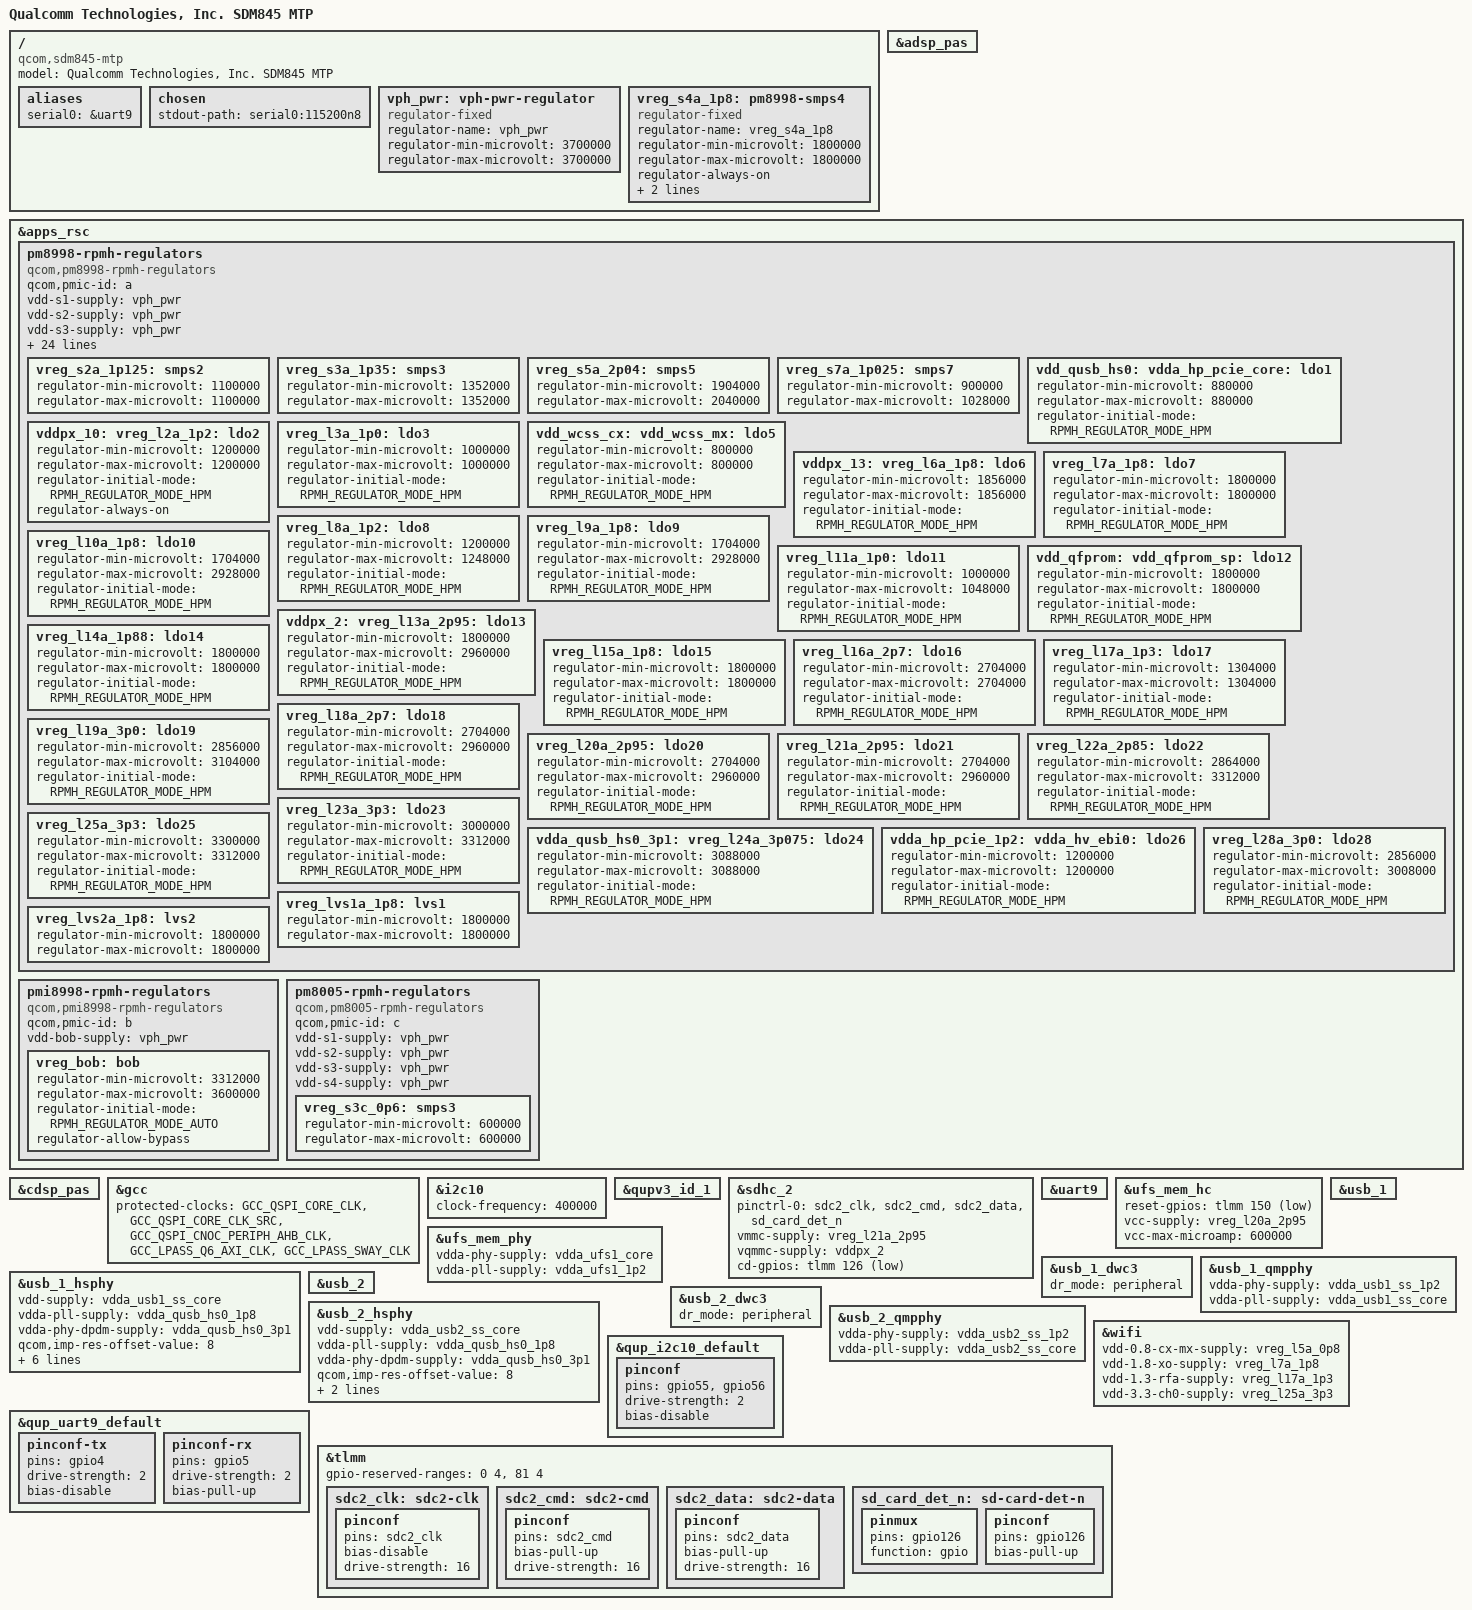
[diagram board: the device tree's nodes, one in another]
// SPDX-License-Identifier: GPL-2.0
/*
 * SDM845 MTP board device tree source
 *
 * Copyright (c) 2018, The Linux Foundation. All rights reserved.
 */

/dts-v1/;

#include <dt-bindings/gpio/gpio.h>
#include <dt-bindings/regulator/qcom,rpmh-regulator.h>
#include "sdm845.dtsi"

/ {
	model = "Qualcomm Technologies, Inc. SDM845 MTP";
	compatible = "qcom,sdm845-mtp";

	aliases {
		serial0 = &uart9;
	};

	chosen {
		stdout-path = "serial0:115200n8";
	};

	vph_pwr: vph-pwr-regulator {
		compatible = "regulator-fixed";
		regulator-name = "vph_pwr";
		regulator-min-microvolt = <3700000>;
		regulator-max-microvolt = <3700000>;
	};

	/*
	 * Apparently RPMh does not provide support for PM8998 S4 because it
	 * is always-on; model it as a fixed regulator.
	 */
	vreg_s4a_1p8: pm8998-smps4 {
		compatible = "regulator-fixed";
		regulator-name = "vreg_s4a_1p8";

		regulator-min-microvolt = <1800000>;
		regulator-max-microvolt = <1800000>;

		regulator-always-on;
		regulator-boot-on;

		vin-supply = <&vph_pwr>;
	};
};

&adsp_pas {
	status = "okay";
};

&apps_rsc {
	pm8998-rpmh-regulators {
		compatible = "qcom,pm8998-rpmh-regulators";
		qcom,pmic-id = "a";

		vdd-s1-supply = <&vph_pwr>;
		vdd-s2-supply = <&vph_pwr>;
		vdd-s3-supply = <&vph_pwr>;
		vdd-s4-supply = <&vph_pwr>;
		vdd-s5-supply = <&vph_pwr>;
		vdd-s6-supply = <&vph_pwr>;
		vdd-s7-supply = <&vph_pwr>;
		vdd-s8-supply = <&vph_pwr>;
		vdd-s9-supply = <&vph_pwr>;
		vdd-s10-supply = <&vph_pwr>;
		vdd-s11-supply = <&vph_pwr>;
		vdd-s12-supply = <&vph_pwr>;
		vdd-s13-supply = <&vph_pwr>;
		vdd-l1-l27-supply = <&vreg_s7a_1p025>;
		vdd-l2-l8-l17-supply = <&vreg_s3a_1p35>;
		vdd-l3-l11-supply = <&vreg_s7a_1p025>;
		vdd-l4-l5-supply = <&vreg_s7a_1p025>;
		vdd-l6-supply = <&vph_pwr>;
		vdd-l7-l12-l14-l15-supply = <&vreg_s5a_2p04>;
		vdd-l9-supply = <&vreg_bob>;
		vdd-l10-l23-l25-supply = <&vreg_bob>;
		vdd-l13-l19-l21-supply = <&vreg_bob>;
		vdd-l16-l28-supply = <&vreg_bob>;
		vdd-l18-l22-supply = <&vreg_bob>;
		vdd-l20-l24-supply = <&vreg_bob>;
		vdd-l26-supply = <&vreg_s3a_1p35>;
		vin-lvs-1-2-supply = <&vreg_s4a_1p8>;

		vreg_s2a_1p125: smps2 {
			regulator-min-microvolt = <1100000>;
			regulator-max-microvolt = <1100000>;
		};

		vreg_s3a_1p35: smps3 {
			regulator-min-microvolt = <1352000>;
			regulator-max-microvolt = <1352000>;
		};

		vreg_s5a_2p04: smps5 {
			regulator-min-microvolt = <1904000>;
			regulator-max-microvolt = <2040000>;
		};

		vreg_s7a_1p025: smps7 {
			regulator-min-microvolt = <900000>;
			regulator-max-microvolt = <1028000>;
		};

		vdd_qusb_hs0:
		vdda_hp_pcie_core:
		vdda_mipi_csi0_0p9:
		vdda_mipi_csi1_0p9:
		vdda_mipi_csi2_0p9:
		vdda_mipi_dsi0_pll:
		vdda_mipi_dsi1_pll:
		vdda_qlink_lv:
		vdda_qlink_lv_ck:
		vdda_qrefs_0p875:
		vdda_pcie_core:
		vdda_pll_cc_ebi01:
		vdda_pll_cc_ebi23:
		vdda_sp_sensor:
		vdda_ufs1_core:
		vdda_ufs2_core:
		vdda_usb1_ss_core:
		vdda_usb2_ss_core:
		vreg_l1a_0p875: ldo1 {
			regulator-min-microvolt = <880000>;
			regulator-max-microvolt = <880000>;
			regulator-initial-mode = <RPMH_REGULATOR_MODE_HPM>;
		};

		vddpx_10:
		vreg_l2a_1p2: ldo2 {
			regulator-min-microvolt = <1200000>;
			regulator-max-microvolt = <1200000>;
			regulator-initial-mode = <RPMH_REGULATOR_MODE_HPM>;
			regulator-always-on;
		};

		vreg_l3a_1p0: ldo3 {
			regulator-min-microvolt = <1000000>;
			regulator-max-microvolt = <1000000>;
			regulator-initial-mode = <RPMH_REGULATOR_MODE_HPM>;
		};

		vdd_wcss_cx:
		vdd_wcss_mx:
		vdda_wcss_pll:
		vreg_l5a_0p8: ldo5 {
			regulator-min-microvolt = <800000>;
			regulator-max-microvolt = <800000>;
			regulator-initial-mode = <RPMH_REGULATOR_MODE_HPM>;
		};

		vddpx_13:
		vreg_l6a_1p8: ldo6 {
			regulator-min-microvolt = <1856000>;
			regulator-max-microvolt = <1856000>;
			regulator-initial-mode = <RPMH_REGULATOR_MODE_HPM>;
		};

		vreg_l7a_1p8: ldo7 {
			regulator-min-microvolt = <1800000>;
			regulator-max-microvolt = <1800000>;
			regulator-initial-mode = <RPMH_REGULATOR_MODE_HPM>;
		};

		vreg_l8a_1p2: ldo8 {
			regulator-min-microvolt = <1200000>;
			regulator-max-microvolt = <1248000>;
			regulator-initial-mode = <RPMH_REGULATOR_MODE_HPM>;
		};

		vreg_l9a_1p8: ldo9 {
			regulator-min-microvolt = <1704000>;
			regulator-max-microvolt = <2928000>;
			regulator-initial-mode = <RPMH_REGULATOR_MODE_HPM>;
		};

		vreg_l10a_1p8: ldo10 {
			regulator-min-microvolt = <1704000>;
			regulator-max-microvolt = <2928000>;
			regulator-initial-mode = <RPMH_REGULATOR_MODE_HPM>;
		};

		vreg_l11a_1p0: ldo11 {
			regulator-min-microvolt = <1000000>;
			regulator-max-microvolt = <1048000>;
			regulator-initial-mode = <RPMH_REGULATOR_MODE_HPM>;
		};

		vdd_qfprom:
		vdd_qfprom_sp:
		vdda_apc1_cs_1p8:
		vdda_gfx_cs_1p8:
		vdda_qrefs_1p8:
		vdda_qusb_hs0_1p8:
		vddpx_11:
		vreg_l12a_1p8: ldo12 {
			regulator-min-microvolt = <1800000>;
			regulator-max-microvolt = <1800000>;
			regulator-initial-mode = <RPMH_REGULATOR_MODE_HPM>;
		};

		vddpx_2:
		vreg_l13a_2p95: ldo13 {
			regulator-min-microvolt = <1800000>;
			regulator-max-microvolt = <2960000>;
			regulator-initial-mode = <RPMH_REGULATOR_MODE_HPM>;
		};

		vreg_l14a_1p88: ldo14 {
			regulator-min-microvolt = <1800000>;
			regulator-max-microvolt = <1800000>;
			regulator-initial-mode = <RPMH_REGULATOR_MODE_HPM>;
		};

		vreg_l15a_1p8: ldo15 {
			regulator-min-microvolt = <1800000>;
			regulator-max-microvolt = <1800000>;
			regulator-initial-mode = <RPMH_REGULATOR_MODE_HPM>;
		};

		vreg_l16a_2p7: ldo16 {
			regulator-min-microvolt = <2704000>;
			regulator-max-microvolt = <2704000>;
			regulator-initial-mode = <RPMH_REGULATOR_MODE_HPM>;
		};

		vreg_l17a_1p3: ldo17 {
			regulator-min-microvolt = <1304000>;
			regulator-max-microvolt = <1304000>;
			regulator-initial-mode = <RPMH_REGULATOR_MODE_HPM>;
		};

		vreg_l18a_2p7: ldo18 {
			regulator-min-microvolt = <2704000>;
			regulator-max-microvolt = <2960000>;
			regulator-initial-mode = <RPMH_REGULATOR_MODE_HPM>;
		};

		vreg_l19a_3p0: ldo19 {
			regulator-min-microvolt = <2856000>;
			regulator-max-microvolt = <3104000>;
			regulator-initial-mode = <RPMH_REGULATOR_MODE_HPM>;
		};

		vreg_l20a_2p95: ldo20 {
			regulator-min-microvolt = <2704000>;
			regulator-max-microvolt = <2960000>;
			regulator-initial-mode = <RPMH_REGULATOR_MODE_HPM>;
		};

		vreg_l21a_2p95: ldo21 {
			regulator-min-microvolt = <2704000>;
			regulator-max-microvolt = <2960000>;
			regulator-initial-mode = <RPMH_REGULATOR_MODE_HPM>;
		};

		vreg_l22a_2p85: ldo22 {
			regulator-min-microvolt = <2864000>;
			regulator-max-microvolt = <3312000>;
			regulator-initial-mode = <RPMH_REGULATOR_MODE_HPM>;
		};

		vreg_l23a_3p3: ldo23 {
			regulator-min-microvolt = <3000000>;
			regulator-max-microvolt = <3312000>;
			regulator-initial-mode = <RPMH_REGULATOR_MODE_HPM>;
		};

		vdda_qusb_hs0_3p1:
		vreg_l24a_3p075: ldo24 {
			regulator-min-microvolt = <3088000>;
			regulator-max-microvolt = <3088000>;
			regulator-initial-mode = <RPMH_REGULATOR_MODE_HPM>;
		};

		vreg_l25a_3p3: ldo25 {
			regulator-min-microvolt = <3300000>;
			regulator-max-microvolt = <3312000>;
			regulator-initial-mode = <RPMH_REGULATOR_MODE_HPM>;
		};

		vdda_hp_pcie_1p2:
		vdda_hv_ebi0:
		vdda_hv_ebi1:
		vdda_hv_ebi2:
		vdda_hv_ebi3:
		vdda_mipi_csi_1p25:
		vdda_mipi_dsi0_1p2:
		vdda_mipi_dsi1_1p2:
		vdda_pcie_1p2:
		vdda_ufs1_1p2:
		vdda_ufs2_1p2:
		vdda_usb1_ss_1p2:
		vdda_usb2_ss_1p2:
		vreg_l26a_1p2: ldo26 {
			regulator-min-microvolt = <1200000>;
			regulator-max-microvolt = <1200000>;
			regulator-initial-mode = <RPMH_REGULATOR_MODE_HPM>;
		};

		vreg_l28a_3p0: ldo28 {
			regulator-min-microvolt = <2856000>;
			regulator-max-microvolt = <3008000>;
			regulator-initial-mode = <RPMH_REGULATOR_MODE_HPM>;
		};

		vreg_lvs1a_1p8: lvs1 {
			regulator-min-microvolt = <1800000>;
			regulator-max-microvolt = <1800000>;
		};

		vreg_lvs2a_1p8: lvs2 {
			regulator-min-microvolt = <1800000>;
			regulator-max-microvolt = <1800000>;
		};
	};

	pmi8998-rpmh-regulators {
		compatible = "qcom,pmi8998-rpmh-regulators";
		qcom,pmic-id = "b";

		vdd-bob-supply = <&vph_pwr>;

		vreg_bob: bob {
			regulator-min-microvolt = <3312000>;
			regulator-max-microvolt = <3600000>;
			regulator-initial-mode = <RPMH_REGULATOR_MODE_AUTO>;
			regulator-allow-bypass;
		};
	};

	pm8005-rpmh-regulators {
		compatible = "qcom,pm8005-rpmh-regulators";
		qcom,pmic-id = "c";

		vdd-s1-supply = <&vph_pwr>;
		vdd-s2-supply = <&vph_pwr>;
		vdd-s3-supply = <&vph_pwr>;
		vdd-s4-supply = <&vph_pwr>;

		vreg_s3c_0p6: smps3 {
			regulator-min-microvolt = <600000>;
			regulator-max-microvolt = <600000>;
		};
	};
};

&cdsp_pas {
	status = "okay";
};

&gcc {
	protected-clocks = <GCC_QSPI_CORE_CLK>,
			   <GCC_QSPI_CORE_CLK_SRC>,
			   <GCC_QSPI_CNOC_PERIPH_AHB_CLK>,
			   <GCC_LPASS_Q6_AXI_CLK>,
			   <GCC_LPASS_SWAY_CLK>;
};

&i2c10 {
	status = "okay";
	clock-frequency = <400000>;
};

&qupv3_id_1 {
	status = "okay";
};

&sdhc_2 {
	status = "okay";

	pinctrl-names = "default";
	pinctrl-0 = <&sdc2_clk &sdc2_cmd &sdc2_data &sd_card_det_n>;

	vmmc-supply = <&vreg_l21a_2p95>;
	vqmmc-supply = <&vddpx_2>;

	cd-gpios = <&tlmm 126 GPIO_ACTIVE_LOW>;
};

&uart9 {
	status = "okay";
};

&ufs_mem_hc {
	status = "okay";

	reset-gpios = <&tlmm 150 GPIO_ACTIVE_LOW>;

	vcc-supply = <&vreg_l20a_2p95>;
	vcc-max-microamp = <600000>;
};

&ufs_mem_phy {
	status = "okay";

	vdda-phy-supply = <&vdda_ufs1_core>;
	vdda-pll-supply = <&vdda_ufs1_1p2>;
};

&usb_1 {
	status = "okay";
};

&usb_1_dwc3 {
	/* Until we have Type C hooked up we'll force this as peripheral. */
	dr_mode = "peripheral";
};

&usb_1_hsphy {
	status = "okay";

	vdd-supply = <&vdda_usb1_ss_core>;
	vdda-pll-supply = <&vdda_qusb_hs0_1p8>;
	vdda-phy-dpdm-supply = <&vdda_qusb_hs0_3p1>;

	qcom,imp-res-offset-value = <8>;
	qcom,hstx-trim-value = <QUSB2_V2_HSTX_TRIM_21_6_MA>;
	qcom,preemphasis-level = <QUSB2_V2_PREEMPHASIS_5_PERCENT>;
	qcom,preemphasis-width = <QUSB2_V2_PREEMPHASIS_WIDTH_HALF_BIT>;
};

&usb_1_qmpphy {
	status = "okay";

	vdda-phy-supply = <&vdda_usb1_ss_1p2>;
	vdda-pll-supply = <&vdda_usb1_ss_core>;
};

&usb_2 {
	status = "okay";
};

&usb_2_dwc3 {
	/*
	 * Though the USB block on SDM845 can support host, there's no vbus
	 * signal for this port on MTP.  Thus (unless you have a non-compliant
	 * hub that works without vbus) the only sensible thing is to force
	 * peripheral mode.
	 */
	dr_mode = "peripheral";
};

&usb_2_hsphy {
	status = "okay";

	vdd-supply = <&vdda_usb2_ss_core>;
	vdda-pll-supply = <&vdda_qusb_hs0_1p8>;
	vdda-phy-dpdm-supply = <&vdda_qusb_hs0_3p1>;

	qcom,imp-res-offset-value = <8>;
	qcom,hstx-trim-value = <QUSB2_V2_HSTX_TRIM_22_8_MA>;
};

&usb_2_qmpphy {
	status = "okay";

	vdda-phy-supply = <&vdda_usb2_ss_1p2>;
	vdda-pll-supply = <&vdda_usb2_ss_core>;
};

&wifi {
	status = "okay";
	vdd-0.8-cx-mx-supply = <&vreg_l5a_0p8>;
	vdd-1.8-xo-supply = <&vreg_l7a_1p8>;
	vdd-1.3-rfa-supply = <&vreg_l17a_1p3>;
	vdd-3.3-ch0-supply = <&vreg_l25a_3p3>;
};

/* PINCTRL - additions to nodes defined in sdm845.dtsi */

&qup_i2c10_default {
	pinconf {
		pins = "gpio55", "gpio56";
		drive-strength = <2>;
		bias-disable;
	};
};

&qup_uart9_default {
	pinconf-tx {
		pins = "gpio4";
		drive-strength = <2>;
		bias-disable;
	};

	pinconf-rx {
		pins = "gpio5";
		drive-strength = <2>;
		bias-pull-up;
	};
};

&tlmm {
	gpio-reserved-ranges = <0 4>, <81 4>;

	sdc2_clk: sdc2-clk {
		pinconf {
			pins = "sdc2_clk";
			bias-disable;

			/*
			 * It seems that mmc_test reports errors if drive
			 * strength is not 16 on clk, cmd, and data pins.
			 */
			drive-strength = <16>;
		};
	};

	sdc2_cmd: sdc2-cmd {
		pinconf {
			pins = "sdc2_cmd";
			bias-pull-up;
			drive-strength = <16>;
		};
	};

	sdc2_data: sdc2-data {
		pinconf {
			pins = "sdc2_data";
			bias-pull-up;
			drive-strength = <16>;
		};
	};

	sd_card_det_n: sd-card-det-n {
		pinmux {
			pins = "gpio126";
			function = "gpio";
		};

		pinconf {
			pins = "gpio126";
			bias-pull-up;
		};
	};
};
